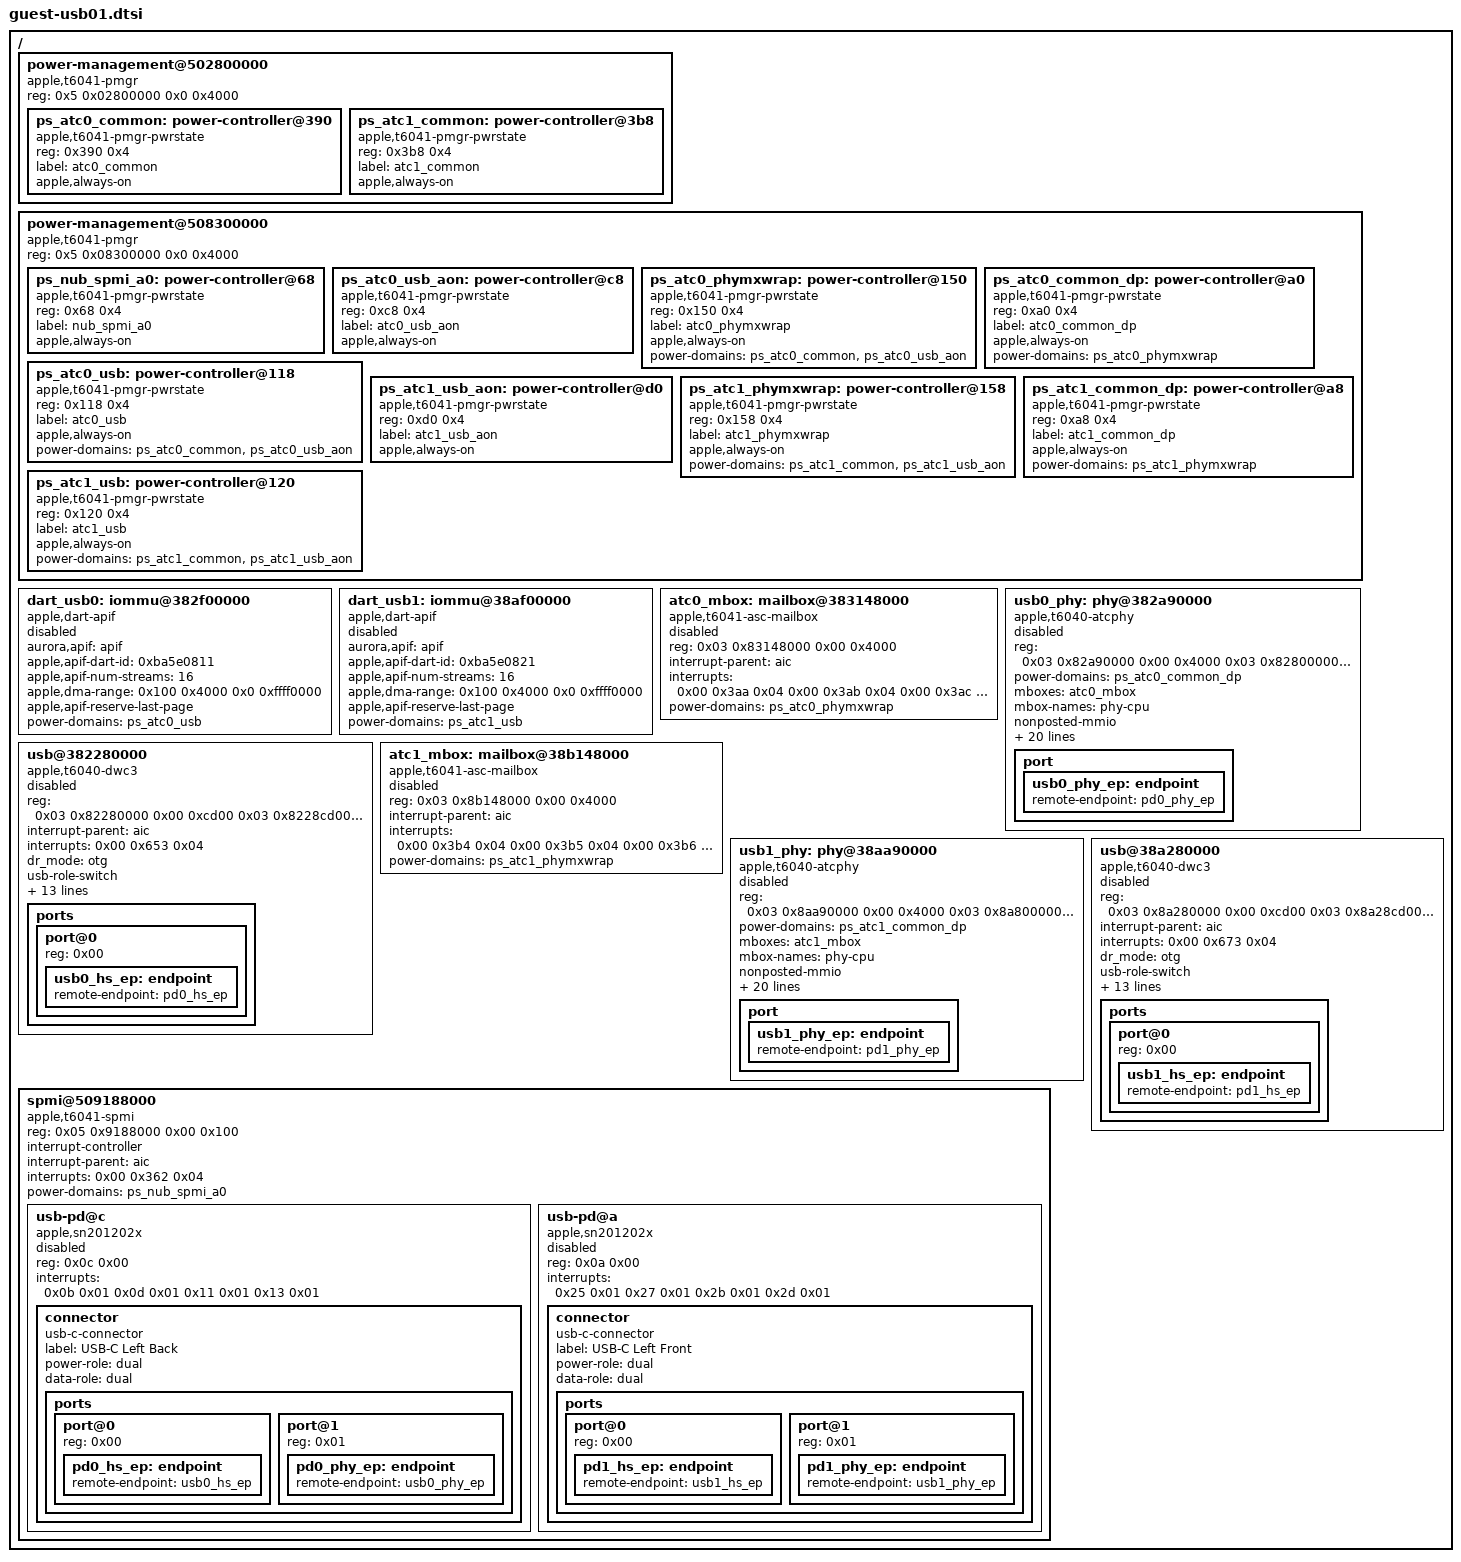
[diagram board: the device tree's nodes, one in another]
// SPDX-License-Identifier: GPL-2.0-only
// F35 final: the two left USB-C ports (ATC0 = Left Back, ATC1 = Left Front) in the daily DT's host/OTG profile: the full
// F38: back to the F35 mhold-ua0/ua1 gates (F36.2 disabled them); the initrd holds both masters until their DART unit is bound
// atc-phy register set and its "phy-cpu" RTKit mailbox (SuperSpeed PHY processor), the PD controllers on nub-spmi-a0,
// dwc3 behind dart-usb0/dart-usb1 (the dart-usb2 pattern proven on HW). Every page is SPTM Table B (check-io.py);
// the DART pages go through apple,dart-apif. Gated per port: "mhold-ua0"/"mhold-ua1" flip to okay when the monitor's
// dart facts match. The PHY processor never ran under the monitor: the sequencer brings each port up as its own late step.
/ {
	// power states of the two left USB-C ports (daily DT, all always-on under the monitor like the atc2 ones)
	power-management@502800000 {
		compatible = "apple,t6041-pmgr", "apple,pmgr", "syscon", "simple-mfd";
		#address-cells = <1>; #size-cells = <1>;
		reg = <0x5 0x02800000 0x0 0x4000>;
		ps_atc0_common: power-controller@390 { compatible = "apple,t6041-pmgr-pwrstate", "apple,pmgr-pwrstate"; reg = <0x390 0x4>; #power-domain-cells = <0>; #reset-cells = <0>; label = "atc0_common"; apple,always-on; };
		ps_atc1_common: power-controller@3b8 { compatible = "apple,t6041-pmgr-pwrstate", "apple,pmgr-pwrstate"; reg = <0x3b8 0x4>; #power-domain-cells = <0>; #reset-cells = <0>; label = "atc1_common"; apple,always-on; };
	};
	power-management@508300000 {
		compatible = "apple,t6041-pmgr", "apple,pmgr", "syscon", "simple-mfd";
		#address-cells = <1>; #size-cells = <1>;
		reg = <0x5 0x08300000 0x0 0x4000>;
		ps_nub_spmi_a0: power-controller@68 { compatible = "apple,t6041-pmgr-pwrstate", "apple,pmgr-pwrstate"; reg = <0x68 0x4>; #power-domain-cells = <0>; #reset-cells = <0>; label = "nub_spmi_a0"; apple,always-on; };
		ps_atc0_usb_aon: power-controller@c8 { compatible = "apple,t6041-pmgr-pwrstate", "apple,pmgr-pwrstate"; reg = <0xc8 0x4>; #power-domain-cells = <0>; #reset-cells = <0>; label = "atc0_usb_aon"; apple,always-on; };
		ps_atc0_phymxwrap: power-controller@150 { compatible = "apple,t6041-pmgr-pwrstate", "apple,pmgr-pwrstate"; reg = <0x150 0x4>; #power-domain-cells = <0>; #reset-cells = <0>; label = "atc0_phymxwrap"; apple,always-on; power-domains = <&ps_atc0_common>, <&ps_atc0_usb_aon>; };
		ps_atc0_common_dp: power-controller@a0 { compatible = "apple,t6041-pmgr-pwrstate", "apple,pmgr-pwrstate"; reg = <0xa0 0x4>; #power-domain-cells = <0>; #reset-cells = <0>; label = "atc0_common_dp"; apple,always-on; power-domains = <&ps_atc0_phymxwrap>; };
		ps_atc0_usb: power-controller@118 { compatible = "apple,t6041-pmgr-pwrstate", "apple,pmgr-pwrstate"; reg = <0x118 0x4>; #power-domain-cells = <0>; #reset-cells = <0>; label = "atc0_usb"; apple,always-on; power-domains = <&ps_atc0_common>, <&ps_atc0_usb_aon>; };
		ps_atc1_usb_aon: power-controller@d0 { compatible = "apple,t6041-pmgr-pwrstate", "apple,pmgr-pwrstate"; reg = <0xd0 0x4>; #power-domain-cells = <0>; #reset-cells = <0>; label = "atc1_usb_aon"; apple,always-on; };
		ps_atc1_phymxwrap: power-controller@158 { compatible = "apple,t6041-pmgr-pwrstate", "apple,pmgr-pwrstate"; reg = <0x158 0x4>; #power-domain-cells = <0>; #reset-cells = <0>; label = "atc1_phymxwrap"; apple,always-on; power-domains = <&ps_atc1_common>, <&ps_atc1_usb_aon>; };
		ps_atc1_common_dp: power-controller@a8 { compatible = "apple,t6041-pmgr-pwrstate", "apple,pmgr-pwrstate"; reg = <0xa8 0x4>; #power-domain-cells = <0>; #reset-cells = <0>; label = "atc1_common_dp"; apple,always-on; power-domains = <&ps_atc1_phymxwrap>; };
		ps_atc1_usb: power-controller@120 { compatible = "apple,t6041-pmgr-pwrstate", "apple,pmgr-pwrstate"; reg = <0x120 0x4>; #power-domain-cells = <0>; #reset-cells = <0>; label = "atc1_usb"; apple,always-on; power-domains = <&ps_atc1_common>, <&ps_atc1_usb_aon>; };
	};
	dart_usb0: iommu@382f00000 {
		compatible = "apple,dart-apif";
		#iommu-cells = <1>;
		aurora,apif = <&apif>;
		apple,apif-dart-id = <0xba5e0811>;   // live ADT dart-usb0 (0xe); patched by the monitor when its checks pass
		apple,apif-num-streams = <16>;
		apple,dma-range = <0x100 0x4000 0x0 0xffff0000>;
		apple,apif-reserve-last-page;
		power-domains = <&ps_atc0_usb>;
		status = "mhold-ua0";
	};
	dart_usb1: iommu@38af00000 {
		compatible = "apple,dart-apif";
		#iommu-cells = <1>;
		aurora,apif = <&apif>;
		apple,apif-dart-id = <0xba5e0821>;   // live ADT dart-usb1 (0xf)
		apple,apif-num-streams = <16>;
		apple,dma-range = <0x100 0x4000 0x0 0xffff0000>;
		apple,apif-reserve-last-page;
		power-domains = <&ps_atc1_usb>;
		status = "mhold-ua1";
	};
	atc0_mbox: mailbox@383148000 {
		compatible = "apple,t6041-asc-mailbox", "apple,asc-mailbox-v4";
	status = "mhold-ua0";
		reg = <0x03 0x83148000 0x00 0x4000>;
		interrupt-parent = <&aic>;
		interrupts = <0x00 0x3aa 0x04 0x00 0x3ab 0x04 0x00 0x3ac 0x04 0x00 0x3ad 0x04>;
		interrupt-names = "send-empty", "send-not-empty", "recv-empty", "recv-not-empty";
		#mbox-cells = <0x00>;
		power-domains = <&ps_atc0_phymxwrap>;
	};
	usb0_phy: phy@382a90000 {
		compatible = "apple,t6040-atcphy";
	status = "mhold-ua0";
		reg = <0x03 0x82a90000 0x00 0x4000 0x03 0x82800000 0x00 0x4000 0x03 0x82a84000 0x00 0x4000 0x03 0x83000000 0x00 0x30000 0x03 0x83200000 0x00 0x4000 0x03 0x83140000 0x00 0x4000 0x03 0x830c0000 0x00 0x10000 0x03 0x80000000 0x00 0x8000 0x03 0x80020000 0x00 0x4000 0x03 0x83244000 0x00 0x4000 0x03 0x83250000 0x00 0x4000>;
		reg-names = "bank0", "bank1", "pipehandler", "core", "cfg", "cpu", "cpu-data", "axi2af", "axi2af-lioa", "fabric", "common-cfg";
		#phy-cells = <0x01>;
		#reset-cells = <0x00>;
		power-domains = <&ps_atc0_common_dp>;
		mboxes = <&atc0_mbox>;
		mbox-names = "phy-cpu";
		nonposted-mmio;
		orientation-switch;
		apple,tunable-axi2af = <0x00 0x800000ff 0x8000001d 0x04 0x80ff00ff 0x801d0003 0x08 0x80ff00ff 0x801d0003 0x0c 0x80ff00ff 0x801d0005 0x10 0x80ff00ff 0x801d0003 0x14 0x80ff00ff 0x801d0003 0x18 0x80ff00ff 0x801d0003 0x1c 0x80ff00ff 0x801d0003 0x20 0x800000ff 0x80000016 0x24 0x800000ff 0x8000003a 0x28 0x80ff00ff 0x803a0006 0x2c 0x80ff00ff 0x803a0006 0x30 0x80ff00ff 0x803a0006 0x34 0x80ff00ff 0x803a0006 0x38 0x80ff00ff 0x803a0006 0x3c 0x80ff00ff 0x803a0006 0x40 0x800000ff 0x80000016 0x44 0x800000ff 0x80000016 0x48 0x800000ff 0x80000016 0x100 0xff 0xff 0x108 0xffff0006 0x100000 0x304 0x3f3f0000 0x4040000 0x308 0xfffff 0x1681 0x30c 0xfffff 0x1680 0x310 0x70000fff 0x1e0 0x314 0xf0000fff 0x800001e0 0x318 0x70000fff 0x1e0 0x31c 0xf0000fff 0x800001e0 0x320 0x70000fff 0x5a0 0x324 0xf0000fff 0x800005a0 0x328 0x70000fff 0x5a0 0x32c 0xf0000fff 0x800005a0 0x330 0x70000fff 0x5a0 0x334 0xf0000fff 0x800005a0 0x338 0x70000fff 0x5a0 0x33c 0x70000fff 0x5a0 0x340 0x70000fff 0x5a0 0x344 0x70000fff 0x5a0 0x348 0x70000fff 0x5a0 0x34c 0x70000fff 0x5a0 0x350 0x70000fff 0x5a0 0x358 0xffffffff 0xffff 0x35c 0xffffffff 0xffff 0x408 0xffff0020 0x190020 0x40c 0xfffff 0x1681 0x410 0xfffff 0x1680 0x414 0x70000fff 0x1e0 0x418 0x70000fff 0x1e0 0x41c 0x70000fff 0x1e0 0x420 0x70000fff 0x1e0 0x424 0x70000fff 0x5a0 0x428 0x70000fff 0x5a0 0x42c 0x70000fff 0x5a0 0x430 0x70000fff 0x5a0 0x434 0x70000fff 0x5a0 0x438 0x70000fff 0x5a0 0x43c 0x70000fff 0x5a0 0x440 0x70000fff 0x5a0 0x444 0x70000fff 0x5a0 0x448 0x70000fff 0x5a0 0x44c 0x70000fff 0x5a0 0x450 0x70000fff 0x5a0 0x454 0x70000fff 0x5a0 0x948 0x7ff07ff 0x280000 0xa48 0x7ff07ff 0x400040 0xb48 0x7ff07ff 0xb8010e 0xc48 0x7ff07ff 0x400020 0xd48 0x7ff07ff 0x8a008a 0x1000 0xffffffff 0x7fffffff 0x4008 0x01 0x01 0x400c 0x01 0x01 0x4014 0x01 0x01 0x4018 0x01 0x00 0x401c 0x01 0x01>;
		apple,tunable-fabric = <0x04 0x3f003f 0x200020 0x0c 0xf1 0xa1 0x10 0x801f 0x04 0x18 0x3f003f 0x200020 0x20 0xf1 0xa1 0x24 0x801f 0x04 0x2c 0xff00ff 0x960096 0x34 0xf1 0x71 0x38 0x801f 0x04 0x40 0x3f 0x20 0x48 0x801f 0x04 0x50 0x7f007f 0x450045 0x58 0x801f 0x04 0x60 0x3f 0x20 0x68 0x801f 0x04 0x70 0x01 0x01 0x74 0x801f 0x04 0x7c 0x7f007f 0x400040 0x80 0xf1 0x11 0x84 0x01 0x01 0x88 0x01 0x01 0x8c 0x801f 0x04 0x94 0x1f001f 0x100010 0x98 0xf1 0x11 0x9c 0x801f 0x04 0xa4 0xff 0xe0 0xa8 0x801f 0x04 0xb0 0x3f 0x20 0xb8 0x801f 0x04 0xc0 0x3f 0x20 0xc8 0x801f 0x04 0xd0 0x1f001f 0x100010 0xd8 0x01 0x01 0xdc 0x01 0x01 0xe0 0x801f 0x04 0xe8 0x0f 0x08 0xec 0x801f 0x04 0xf4 0xffffffff 0x1010101 0xf8 0x801f 0x04 0x100 0x01 0x01 0x104 0x01 0x01 0x108 0x801f 0x04 0x110 0x801f 0x04 0x118 0x801f 0x04 0x120 0x01 0x01 0x124 0x01 0x01 0x128 0x801f 0x04 0x130 0xffffffff 0x1010101 0x134 0x801f 0x04 0x13c 0x01 0x01 0x140 0x01 0x01 0x144 0x801f 0x04 0x14c 0x01 0x01 0x150 0x01 0x01 0x154 0x801f 0x04 0x15c 0x801f 0x04 0x164 0xffffffff 0x1010101 0x168 0xffff 0x101 0x16c 0x801f 0x04 0x174 0x01 0x01 0x178 0x01 0x01 0x17c 0x801f 0x04 0x184 0x01 0x01 0x188 0x01 0x01 0x18c 0x801f 0x04>;
		apple,tunable-common-cfg = <0x08 0x01 0x01>;
		apple,tunable-axi2af-lioa = <0x28 0xfe2f 0x00 0x2c 0x07 0x00 0x30 0x7f 0x00 0x34 0xff 0x00 0x58 0x10b 0x00>;
		apple,tunable-lane0 = <0xd094 0x80000 0x80000 0xd098 0x80000 0x80000 0xd0a4 0x800000 0x800000 0xd0a8 0x200000 0x200000>;
		apple,tunable-lane1 = <0x1d094 0x80000 0x80000 0x1d098 0x80000 0x80000 0x1d0a4 0x800000 0x800000 0x1d0a8 0x200000 0x200000>;
		apple,tunable-aus40cmn-shm = <0xa04 0x7c 0x48>;
		apple,tunable-auspll = <0x3224 0xc00 0x800 0x3230 0x1f 0x0f 0x3240 0x7d8007f 0x4000059 0x32b0 0xb800000 0x1800000 0x32e8 0x60001 0x40001 0x3338 0xf800000 0x7800000>;
		apple,tunable-cio4pll = <0x3a30 0x1f 0x0f 0x3a4c 0xfe7f 0x501e 0x3ab0 0x700000 0x300000 0x3ae8 0x60000 0x20000>;
		apple,tunable-pipehandler = <0x44 0x04 0x04>;
		apple,tunable-usb2-host = <0x08 0x7003 0x03>;
		mode-switch;

		port {

			usb0_phy_ep: endpoint {
				remote-endpoint = <&pd0_phy_ep>;
			};
		};
	};
	usb@382280000 {
		compatible = "apple,t6040-dwc3", "apple,t8103-dwc3";
	status = "mhold-ua0";
		reg = <0x03 0x82280000 0x00 0xcd00 0x03 0x8228cd00 0x00 0x3200 0x03 0x82200000 0x00 0x4000>;
		reg-names = "dwc3-core", "dwc3-apple", "drd-cfg";
		interrupt-parent = <&aic>;
		interrupts = <0x00 0x653 0x04>;
		dr_mode = "otg";
		usb-role-switch;
		role-switch-default-mode = "host";
		iommus = <&dart_usb0 1>;   // SPTM programs the stream on every instance (dart-usb2 pattern, HW F34)
		power-domains = <&ps_atc0_usb>;
		resets = <&usb0_phy>;
		phys = <&usb0_phy 0x03 &usb0_phy 0x04>;
		phy-names = "usb2-phy", "usb3-phy";
		apple,tunable-gbl-default = <0x64 0x02 0x00 0x10 0xfff80000 0x680000>;
		apple,tunable-gbl-host = <0x04 0x1ef00 0x2f00 0x1c 0x100 0x00 0x2c 0xa07ff 0x800c8 0x100 0x2000100 0x2000100 0x504 0x1000 0x00 0x528 0xff0000ff 0x6000006 0x52c 0xff0000ff 0x8000008 0x538 0x800 0x800 0x580 0xffffffff 0x6f000006>;
		apple,tunable-dbg = <0x00 0x08 0x08>;
		apple,tunable-cfg-host = <0x20 0xff 0x1b>;
		apple,tunable-link = <0x20 0x7ff00000 0x4e900000 0x24 0x1f8000 0xb8000 0x60 0x3ffff 0x600>;

		ports {
			#address-cells = <&aic>;
			#size-cells = <0x00>;

			port@0 {
				reg = <0x00>;

				usb0_hs_ep: endpoint {
					remote-endpoint = <&pd0_hs_ep>;
				};
			};
		};
	};
	atc1_mbox: mailbox@38b148000 {
		compatible = "apple,t6041-asc-mailbox", "apple,asc-mailbox-v4";
	status = "mhold-ua1";
		reg = <0x03 0x8b148000 0x00 0x4000>;
		interrupt-parent = <&aic>;
		interrupts = <0x00 0x3b4 0x04 0x00 0x3b5 0x04 0x00 0x3b6 0x04 0x00 0x3b7 0x04>;
		interrupt-names = "send-empty", "send-not-empty", "recv-empty", "recv-not-empty";
		#mbox-cells = <0x00>;
		power-domains = <&ps_atc1_phymxwrap>;
	};
	usb1_phy: phy@38aa90000 {
		compatible = "apple,t6040-atcphy";
	status = "mhold-ua1";
		reg = <0x03 0x8aa90000 0x00 0x4000 0x03 0x8a800000 0x00 0x4000 0x03 0x8aa84000 0x00 0x4000 0x03 0x8b000000 0x00 0x30000 0x03 0x8b200000 0x00 0x4000 0x03 0x8b140000 0x00 0x4000 0x03 0x8b0c0000 0x00 0x10000 0x03 0x88000000 0x00 0x8000 0x03 0x88020000 0x00 0x4000 0x03 0x8b244000 0x00 0x4000 0x03 0x8b250000 0x00 0x4000>;
		reg-names = "bank0", "bank1", "pipehandler", "core", "cfg", "cpu", "cpu-data", "axi2af", "axi2af-lioa", "fabric", "common-cfg";
		#phy-cells = <0x01>;
		#reset-cells = <0x00>;
		power-domains = <&ps_atc1_common_dp>;
		mboxes = <&atc1_mbox>;
		mbox-names = "phy-cpu";
		nonposted-mmio;
		orientation-switch;
		apple,tunable-axi2af = <0x00 0x800000ff 0x8000001c 0x04 0x80ff00ff 0x801b0003 0x08 0x80ff00ff 0x801b0003 0x0c 0x80ff00ff 0x801b0005 0x10 0x80ff00ff 0x801b0003 0x14 0x80ff00ff 0x801b0003 0x18 0x80ff00ff 0x801b0003 0x1c 0x80ff00ff 0x801b0003 0x20 0x800000ff 0x80000015 0x24 0x800000ff 0x80000038 0x28 0x80ff00ff 0x80380006 0x2c 0x80ff00ff 0x80380006 0x30 0x80ff00ff 0x80380006 0x34 0x80ff00ff 0x80380006 0x38 0x80ff00ff 0x80380006 0x3c 0x80ff00ff 0x80380006 0x40 0x800000ff 0x80000015 0x44 0x800000ff 0x80000015 0x48 0x800000ff 0x80000015 0x100 0xff 0xff 0x108 0xffff0006 0x100000 0x304 0x3f3f0000 0x4040000 0x308 0xfffff 0x1681 0x30c 0xfffff 0x1680 0x310 0x70000fff 0x1e0 0x314 0xf0000fff 0x800001e0 0x318 0x70000fff 0x1e0 0x31c 0xf0000fff 0x800001e0 0x320 0x70000fff 0x5a0 0x324 0xf0000fff 0x800005a0 0x328 0x70000fff 0x5a0 0x32c 0xf0000fff 0x800005a0 0x330 0x70000fff 0x5a0 0x334 0xf0000fff 0x800005a0 0x338 0x70000fff 0x5a0 0x33c 0x70000fff 0x5a0 0x340 0x70000fff 0x5a0 0x344 0x70000fff 0x5a0 0x348 0x70000fff 0x5a0 0x34c 0x70000fff 0x5a0 0x350 0x70000fff 0x5a0 0x358 0xffffffff 0xffff 0x35c 0xffffffff 0xffff 0x408 0xffff0020 0x180020 0x40c 0xfffff 0x1681 0x410 0xfffff 0x1680 0x414 0x70000fff 0x1e0 0x418 0x70000fff 0x1e0 0x41c 0x70000fff 0x1e0 0x420 0x70000fff 0x1e0 0x424 0x70000fff 0x5a0 0x428 0x70000fff 0x5a0 0x42c 0x70000fff 0x5a0 0x430 0x70000fff 0x5a0 0x434 0x70000fff 0x5a0 0x438 0x70000fff 0x5a0 0x43c 0x70000fff 0x5a0 0x440 0x70000fff 0x5a0 0x444 0x70000fff 0x5a0 0x448 0x70000fff 0x5a0 0x44c 0x70000fff 0x5a0 0x450 0x70000fff 0x5a0 0x454 0x70000fff 0x5a0 0x948 0x7ff07ff 0x280000 0xa48 0x7ff07ff 0x400040 0xb48 0x7ff07ff 0xb8010e 0xc48 0x7ff07ff 0x400020 0xd48 0x7ff07ff 0x8a008a 0x1000 0xffffffff 0x7fffffff 0x4008 0x01 0x01 0x400c 0x01 0x01 0x4014 0x01 0x01 0x4018 0x01 0x00 0x401c 0x01 0x01>;
		apple,tunable-fabric = <0x04 0x3f003f 0x200020 0x0c 0xf1 0xa1 0x10 0x801f 0x04 0x18 0x3f003f 0x200020 0x20 0xf1 0xa1 0x24 0x801f 0x04 0x2c 0xff00ff 0x960096 0x34 0xf1 0x71 0x38 0x801f 0x04 0x40 0x3f 0x20 0x48 0x801f 0x04 0x50 0x7f007f 0x450045 0x58 0x801f 0x04 0x60 0x3f 0x20 0x68 0x801f 0x04 0x70 0x01 0x01 0x74 0x801f 0x04 0x7c 0x7f007f 0x400040 0x80 0xf1 0x11 0x84 0x01 0x01 0x88 0x01 0x01 0x8c 0x801f 0x04 0x94 0x1f001f 0x100010 0x98 0xf1 0x11 0x9c 0x801f 0x04 0xa4 0xff 0xe0 0xa8 0x801f 0x04 0xb0 0x3f 0x20 0xb8 0x801f 0x04 0xc0 0x3f 0x20 0xc8 0x801f 0x04 0xd0 0x1f001f 0x100010 0xd8 0x01 0x01 0xdc 0x01 0x01 0xe0 0x801f 0x04 0xe8 0x0f 0x08 0xec 0x801f 0x04 0xf4 0xffffffff 0x1010101 0xf8 0x801f 0x04 0x100 0x01 0x01 0x104 0x01 0x01 0x108 0x801f 0x04 0x110 0x801f 0x04 0x118 0x801f 0x04 0x120 0x01 0x01 0x124 0x01 0x01 0x128 0x801f 0x04 0x130 0xffffffff 0x1010101 0x134 0x801f 0x04 0x13c 0x01 0x01 0x140 0x01 0x01 0x144 0x801f 0x04 0x14c 0x01 0x01 0x150 0x01 0x01 0x154 0x801f 0x04 0x15c 0x801f 0x04 0x164 0xffffffff 0x1010101 0x168 0xffff 0x101 0x16c 0x801f 0x04 0x174 0x01 0x01 0x178 0x01 0x01 0x17c 0x801f 0x04 0x184 0x01 0x01 0x188 0x01 0x01 0x18c 0x801f 0x04>;
		apple,tunable-common-cfg = <0x08 0x01 0x01>;
		apple,tunable-axi2af-lioa = <0x28 0xfe2f 0x00 0x2c 0x07 0x00 0x30 0x7f 0x00 0x34 0xff 0x00 0x58 0x10b 0x00>;
		apple,tunable-lane0 = <0xd094 0x80000 0x80000 0xd098 0x80000 0x80000 0xd0a4 0x800000 0x800000 0xd0a8 0x200000 0x200000>;
		apple,tunable-lane1 = <0x1d094 0x80000 0x80000 0x1d098 0x80000 0x80000 0x1d0a4 0x800000 0x800000 0x1d0a8 0x200000 0x200000>;
		apple,tunable-aus40cmn-shm = <0xa04 0x7c 0x4c>;
		apple,tunable-auspll = <0x3224 0xc00 0x800 0x3230 0x1f 0x0f 0x3240 0x7d8007f 0x4000049 0x32b0 0xb800000 0x1800000 0x32e8 0x60001 0x40001 0x3338 0xf800000 0x7800000>;
		apple,tunable-cio4pll = <0x3a30 0x1f 0x0f 0x3a4c 0xfe7f 0x501e 0x3ab0 0x700000 0x300000 0x3ae8 0x60000 0x20000>;
		apple,tunable-pipehandler = <0x44 0x04 0x04>;
		apple,tunable-usb2-host = <0x08 0x7003 0x03>;
		mode-switch;

		port {

			usb1_phy_ep: endpoint {
				remote-endpoint = <&pd1_phy_ep>;
			};
		};
	};
	usb@38a280000 {
		compatible = "apple,t6040-dwc3", "apple,t8103-dwc3";
	status = "mhold-ua1";
		reg = <0x03 0x8a280000 0x00 0xcd00 0x03 0x8a28cd00 0x00 0x3200 0x03 0x8a200000 0x00 0x4000>;
		reg-names = "dwc3-core", "dwc3-apple", "drd-cfg";
		interrupt-parent = <&aic>;
		interrupts = <0x00 0x673 0x04>;
		dr_mode = "otg";
		usb-role-switch;
		role-switch-default-mode = "host";
		iommus = <&dart_usb1 1>;
		power-domains = <&ps_atc1_usb>;
		resets = <&usb1_phy>;
		phys = <&usb1_phy 0x03 &usb1_phy 0x04>;
		phy-names = "usb2-phy", "usb3-phy";
		apple,tunable-gbl-default = <0x64 0x02 0x00 0x10 0xfff80000 0x680000>;
		apple,tunable-gbl-host = <0x04 0x1ef00 0x2f00 0x1c 0x100 0x00 0x2c 0xa07ff 0x800c8 0x100 0x2000100 0x2000100 0x504 0x1000 0x00 0x528 0xff0000ff 0x6000006 0x52c 0xff0000ff 0x8000008 0x538 0x800 0x800 0x580 0xffffffff 0x6f000006>;
		apple,tunable-dbg = <0x00 0x08 0x08>;
		apple,tunable-cfg-host = <0x20 0xff 0x1b>;
		apple,tunable-link = <0x20 0x7ff00000 0x4e900000 0x24 0x1f8000 0xb8000 0x60 0x3ffff 0x600>;

		ports {
			#address-cells = <&aic>;
			#size-cells = <0x00>;

			port@0 {
				reg = <0x00>;

				usb1_hs_ep: endpoint {
					remote-endpoint = <&pd1_hs_ep>;
				};
			};
		};
	};
	spmi@509188000 {
		compatible = "apple,t6041-spmi", "apple,t8103-spmi";
	status = "okay";
		reg = <0x05 0x9188000 0x00 0x100>;
		#address-cells = <0x02>;
		#size-cells = <0x00>;
		#interrupt-cells = <0x02>;
		interrupt-controller;
		interrupt-parent = <&aic>;
		interrupts = <0x00 0x362 0x04>;
		power-domains = <&ps_nub_spmi_a0>;

		usb-pd@c {
			status = "mhold-ua0";
			compatible = "apple,sn201202x";
			reg = <0x0c 0x00>;
			interrupts = <0x0b 0x01 0x0d 0x01 0x11 0x01 0x13 0x01>;
			interrupt-names = "irq", "select", "sleep", "wake";

			connector {
				compatible = "usb-c-connector";
				label = "USB-C Left Back";
				power-role = "dual";
				data-role = "dual";

				ports {
					#address-cells = <0x01>;
					#size-cells = <0x00>;

					port@0 {
						reg = <0x00>;

						pd0_hs_ep: endpoint {
							remote-endpoint = <&usb0_hs_ep>;
						};
					};

					port@1 {
						reg = <0x01>;

						pd0_phy_ep: endpoint {
							remote-endpoint = <&usb0_phy_ep>;
						};
					};

				};
			};
		};

		usb-pd@a {
			status = "mhold-ua1";
			compatible = "apple,sn201202x";
			reg = <0x0a 0x00>;
			interrupts = <0x25 0x01 0x27 0x01 0x2b 0x01 0x2d 0x01>;
			interrupt-names = "irq", "select", "sleep", "wake";

			connector {
				compatible = "usb-c-connector";
				label = "USB-C Left Front";
				power-role = "dual";
				data-role = "dual";

				ports {
					#address-cells = <0x01>;
					#size-cells = <0x00>;

					port@0 {
						reg = <0x00>;

						pd1_hs_ep: endpoint {
							remote-endpoint = <&usb1_hs_ep>;
						};
					};

					port@1 {
						reg = <0x01>;

						pd1_phy_ep: endpoint {
							remote-endpoint = <&usb1_phy_ep>;
						};
					};

				};
			};
		};

	};
};
